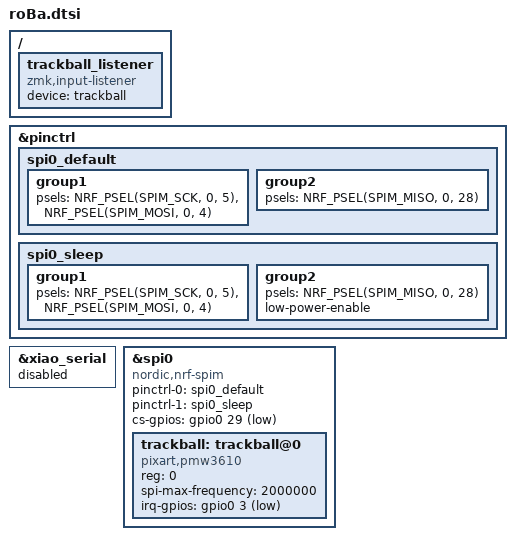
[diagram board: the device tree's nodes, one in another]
#include "roBa.dtsi"

/* ==========================================================================
   1. 不要な機能の完全無効化・解放（発熱対策）
   ========================================================================== 
   dtsi側でD5/D0ピンを掴んでしまっていたロータリーエンコーダーを
   完全に削除（初期化）し、マイコンのピンをクリアな状態に解放します。
*/
/ {
    /delete-node/ encoder_left;
    /delete-node/ encoder_right;

    /* トラックボールのインプットリスナーを有効化 */
    trackball_listener {
        status = "okay";
        compatible = "zmk,input-listener";
        device = <&trackball>;
    };
};

/* ==========================================================================
   2. トラックボール用 SPI通信（SPIM0）ピンアサインの再定義
   ========================================================================== 
   MISOとMOSIが同じピン（0, 4）になっていた重なりを完全に解消します。
   一般的なroBaのトラックボール側配線（D4=MISO、D5=CS）に整合させます。
*/
&pinctrl {
    spi0_default: spi0_default {
        group1 {
            psels = <NRF_PSEL(SPIM_SCK,  0, 5)>,   /* SCK  : Xiao 3番ピン (D3) */
                    <NRF_PSEL(SPIM_MOSI, 0, 4)>;   /* MOSI : Xiao 2番ピン (D2) */
        };
        group2 {
            psels = <NRF_PSEL(SPIM_MISO, 0, 28)>;  /* MISO : Xiao 4番ピン (D4) に完全分離 */
        };
    };

    spi0_sleep: spi0_sleep {
        group1 {
            psels = <NRF_PSEL(SPIM_SCK,  0, 5)>,
                    <NRF_PSEL(SPIM_MOSI, 0, 4)>;
        };
        group2 {
            psels = <NRF_PSEL(SPIM_MISO, 0, 28)>;
            low-power-enable;
        };
    };
};

/* ==========================================================================
   3. トラックボール本体・SPI通信の有効化（競合ピンの修正）
   ========================================================================== */
&xiao_serial { status = "disabled"; };

&spi0 {
    status = "okay";
    compatible = "nordic,nrf-spim";
    pinctrl-0 = <&spi0_default>;
    pinctrl-1 = <&spi0_sleep>;
    pinctrl-names = "default", "sleep";
    cs-gpios = <&gpio0 29 GPIO_ACTIVE_LOW>;      /* CS : Xiao 5番ピン (D5) */

    trackball: trackball@0 {
        status = "okay";
        compatible = "pixart,pmw3610";
        reg = <0>;
        spi-max-frequency = <2000000>;
        
        /* IRQ（割り込みピン）を 1番ピン (D1 = P0.03) に逃がします */
        irq-gpios = <&gpio0 3 (GPIO_ACTIVE_LOW | GPIO_PULL_UP)>; 
    };
};
